# STM32L4S9xx register map
File version: 1.0
Registers are 32-bit, access not given, reset 0x0 unless marked. A register's access mark holds for its fields unless they carry their own. Offsets are from the block's base; [hi:lo] are bit positions; {n}, {i} and the like mark numbered series.

## CRS
Base 0x40006000
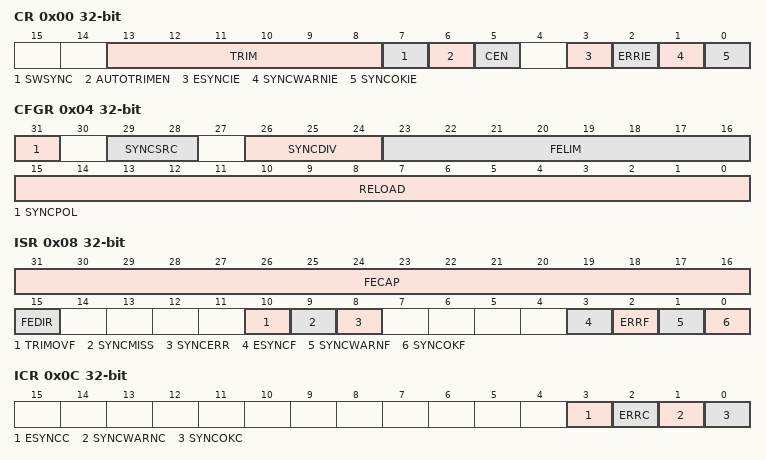
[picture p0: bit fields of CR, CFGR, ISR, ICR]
0x00 CR
  [13:8] TRIM, [7] SWSYNC, [6] AUTOTRIMEN, [5] CEN, [3] ESYNCIE, [2] ERRIE, [1] SYNCWARNIE, [0] SYNCOKIE
0x04 CFGR
  [31] SYNCPOL, [29:28] SYNCSRC, [26:24] SYNCDIV, [23:16] FELIM, [15:0] RELOAD
0x08 ISR
  [31:16] FECAP, [15] FEDIR, [10] TRIMOVF, [9] SYNCMISS, [8] SYNCERR, [3] ESYNCF, [2] ERRF, [1] SYNCWARNF, [0] SYNCOKF
0x0C ICR
  [3] ESYNCC, [2] ERRC, [1] SYNCWARNC, [0] SYNCOKC

## PWR
Base 0x40007000
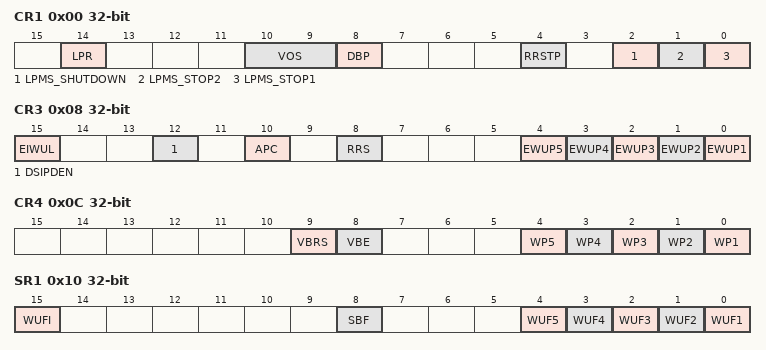
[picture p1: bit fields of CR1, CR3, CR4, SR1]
0x00 CR1
  [14] LPR, [10:9] VOS, [8] DBP, [4] RRSTP, [2] LPMS_SHUTDOWN, [1] LPMS_STOP2, [0] LPMS_STOP1
0x04 CR2
  [10] USV, [9] IOSV, [n+3] PVME{n} (n=1..4), [3] PLS_LEV4, [3:2] PLS_LEV6, [3:1] PLS_LEV7, [0] PVDE
0x08 CR3
  [15] EIWUL, [12] DSIPDEN, [10] APC, [8] RRS, [n-1] EWUP{n} (n=1..5)
0x0C CR4
  [9] VBRS, [8] VBE, [n-1] WP{n} (n=1..5)
0x10 SR1
  [15] WUFI, [8] SBF, [n-1] WUF{n} (n=1..5)
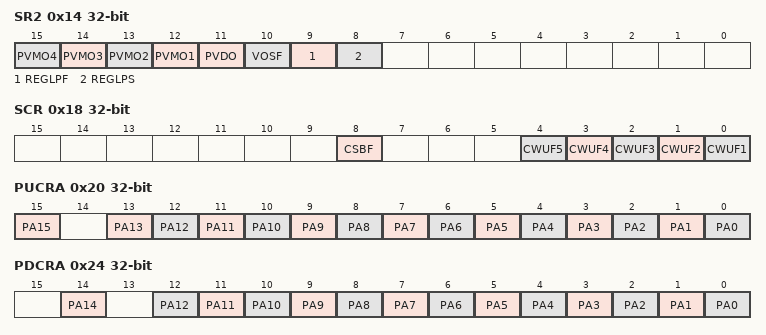
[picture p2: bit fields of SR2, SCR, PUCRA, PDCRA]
0x14 SR2
  [n+11] PVMO{n} (n=1..4), [11] PVDO, [10] VOSF, [9] REGLPF, [8] REGLPS
0x18 SCR
  [8] CSBF, [n-1] CWUF{n} (n=1..5)
0x20 PUCRA
  [15] PA15, [n] PA{n} (n=0..13)
0x24 PDCRA
  [14] PA14, [n] PA{n} (n=0..12)
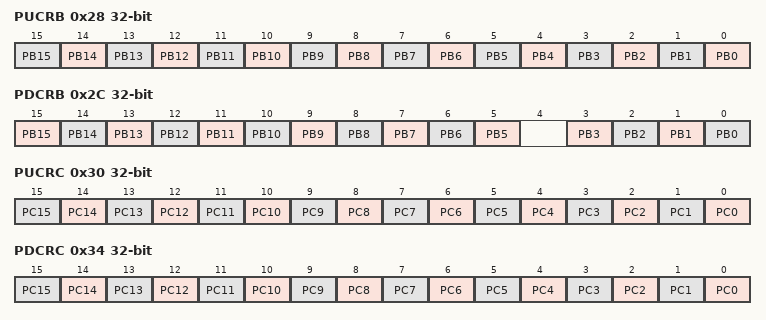
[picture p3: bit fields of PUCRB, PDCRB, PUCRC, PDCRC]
0x28 PUCRB
  [n] PB{n} (n=0..15)
0x2C PDCRB
  [n] PB{n} (n=5..15), [n] PB{n} (n=0..3)
0x30 PUCRC
  [n] PC{n} (n=0..15)
0x34 PDCRC
  [n] PC{n} (n=0..15)
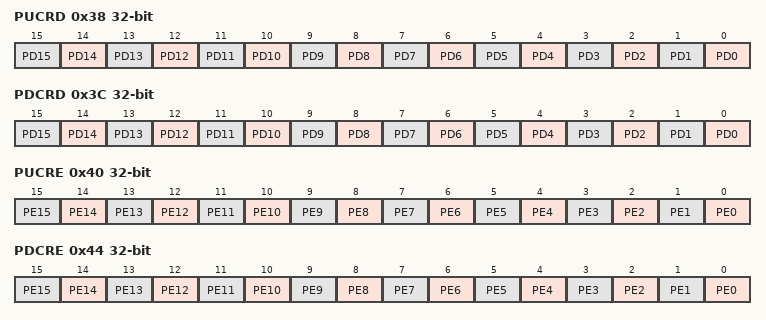
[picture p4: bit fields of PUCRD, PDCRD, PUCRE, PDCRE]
0x38 PUCRD
  [n] PD{n} (n=0..15)
0x3C PDCRD
  [n] PD{n} (n=0..15)
0x40 PUCRE
  [n] PE{n} (n=0..15)
0x44 PDCRE
  [n] PE{n} (n=0..15)
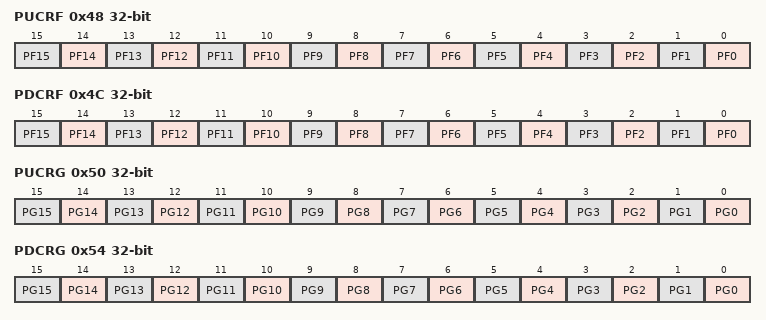
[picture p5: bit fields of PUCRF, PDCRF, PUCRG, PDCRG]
0x48 PUCRF
  [n] PF{n} (n=0..15)
0x4C PDCRF
  [n] PF{n} (n=0..15)
0x50 PUCRG
  [n] PG{n} (n=0..15)
0x54 PDCRG
  [n] PG{n} (n=0..15)
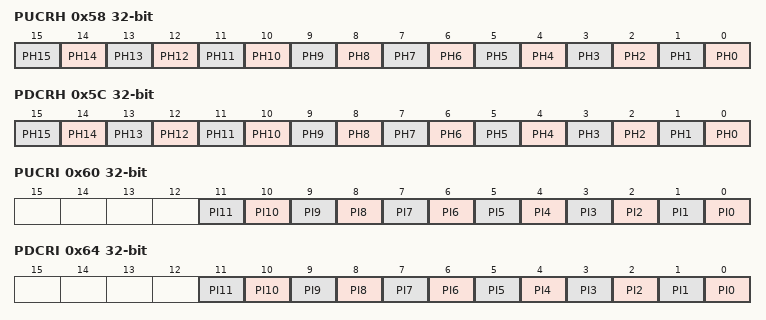
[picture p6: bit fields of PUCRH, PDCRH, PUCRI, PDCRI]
0x58 PUCRH
  [n] PH{n} (n=0..15)
0x5C PDCRH
  [n] PH{n} (n=0..15)
0x60 PUCRI
  [n] PI{n} (n=0..11)
0x64 PDCRI
  [n] PI{n} (n=0..11)
0x80 CR5
  [8] R1MODE

## DAC
Base 0x40007400
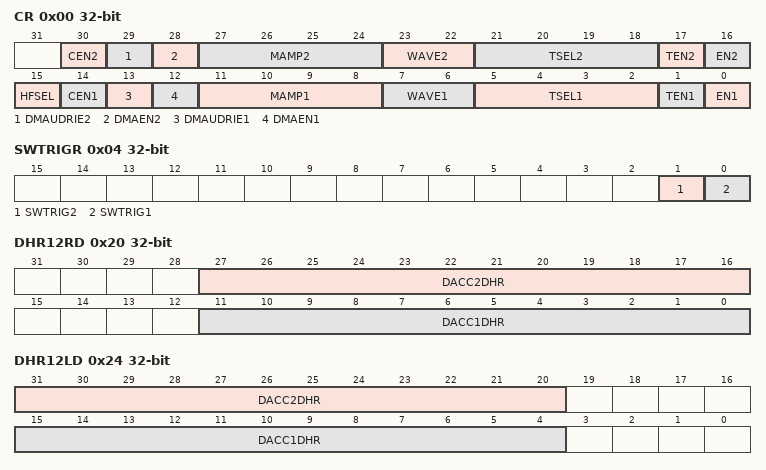
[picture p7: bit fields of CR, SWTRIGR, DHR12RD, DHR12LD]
0x00 CR
  [30] CEN2, [29] DMAUDRIE2, [28] DMAEN2, [27:24] MAMP2, [23:22] WAVE2, [21:18] TSEL2, [17] TEN2, [16] EN2, [15] HFSEL, [14] CEN1, [13] DMAUDRIE1, [12] DMAEN1, [11:8] MAMP1, [7:6] WAVE1, [5:2] TSEL1, [1] TEN1, [0] EN1
0x04 SWTRIGR
  [1] SWTRIG2, [0] SWTRIG1
0x08 DHR12R1
  [11:0] DACC1DHR
0x0C DHR12L1
  [15:4] DACC1DHR
0x10 DHR8R1
  [7:0] DACC1DHR
0x14 DHR12R2
  [11:0] DACC2DHR
0x18 DHR12L2
  [15:4] DACC2DHR
0x1C DHR8R2
  [7:0] DACC2DHR
0x20 DHR12RD
  [27:16] DACC2DHR, [11:0] DACC1DHR
0x24 DHR12LD
  [31:20] DACC2DHR, [15:4] DACC1DHR
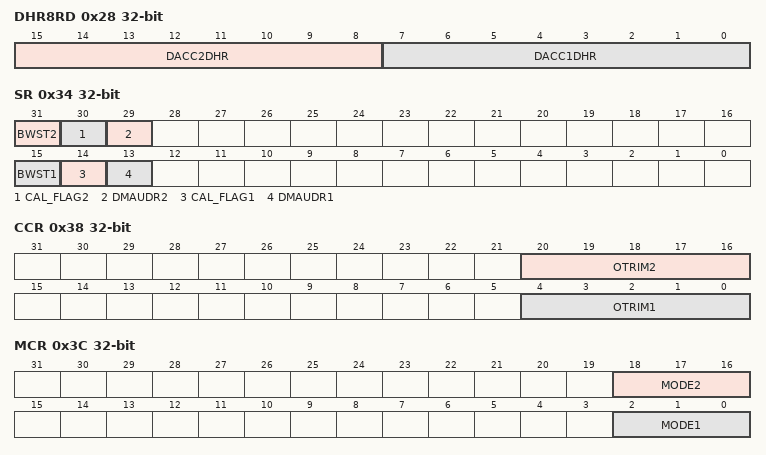
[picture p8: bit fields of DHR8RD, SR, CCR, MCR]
0x28 DHR8RD
  [15:8] DACC2DHR, [7:0] DACC1DHR
0x2C DOR1
  [11:0] DACC1DOR
0x30 DOR2
  [11:0] DACC2DOR
0x34 SR
  [31] BWST2, [30] CAL_FLAG2, [29] DMAUDR2, [15] BWST1, [14] CAL_FLAG1, [13] DMAUDR1
0x38 CCR
  [20:16] OTRIM2, [4:0] OTRIM1
0x3C MCR
  [18:16] MODE2, [2:0] MODE1
0x40 SHSR1
  [9:0] TSAMPLE1
0x44 SHSR2
  [9:0] TSAMPLE2
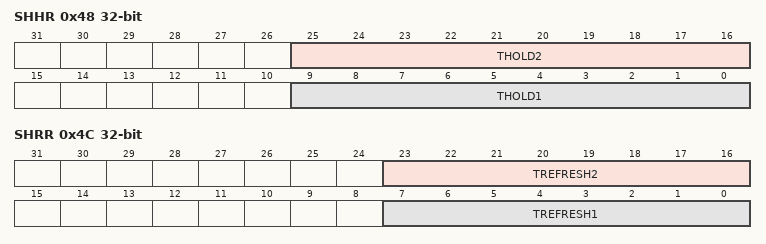
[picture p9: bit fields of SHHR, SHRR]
0x48 SHHR
  [25:16] THOLD2, [9:0] THOLD1
0x4C SHRR
  [23:16] TREFRESH2, [7:0] TREFRESH1

## DAC1
Base 0x40007400
Registers as DAC; these are added or differ:
0x08 DHR12R1
  [11:0] DACC1DHR
0x0C DHR12L1
  [15:4] DACC1DHR
0x10 DHR8R1
  [7:0] DACC1DHR
0x14 DHR12R2
  [11:0] DACC2DHR
0x18 DHR12L2
  [15:4] DACC2DHR
0x1C DHR8R2
  [7:0] DACC2DHR
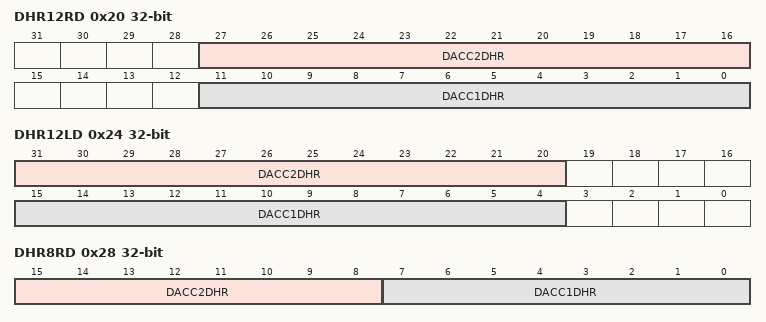
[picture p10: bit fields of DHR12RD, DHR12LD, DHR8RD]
0x20 DHR12RD
  [27:16] DACC2DHR, [11:0] DACC1DHR
0x24 DHR12LD
  [31:20] DACC2DHR, [15:4] DACC1DHR
0x28 DHR8RD
  [15:8] DACC2DHR, [7:0] DACC1DHR
0x2C DOR1
  [11:0] DACC1DOR
0x30 DOR2
  [11:0] DACC2DOR

## OPAMP1
Base 0x40007800
Same registers: OPAMP2 0x40007810
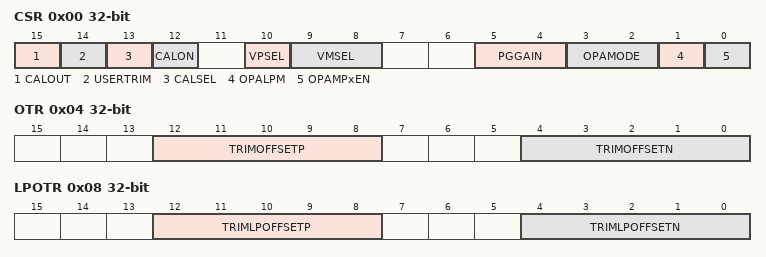
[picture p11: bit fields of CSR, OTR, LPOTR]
0x00 CSR
  [15] CALOUT, [14] USERTRIM, [13] CALSEL, [12] CALON, [10] VPSEL, [9:8] VMSEL, [5:4] PGGAIN, [3:2] OPAMODE, [1] OPALPM, [0] OPAMPxEN
0x04 OTR
  [12:8] TRIMOFFSETP, [4:0] TRIMOFFSETN
0x08 LPOTR
  [12:8] TRIMLPOFFSETP, [4:0] TRIMLPOFFSETN

## LPTIM1
Base 0x40007C00
Same registers: LPTIM2 0x40009400
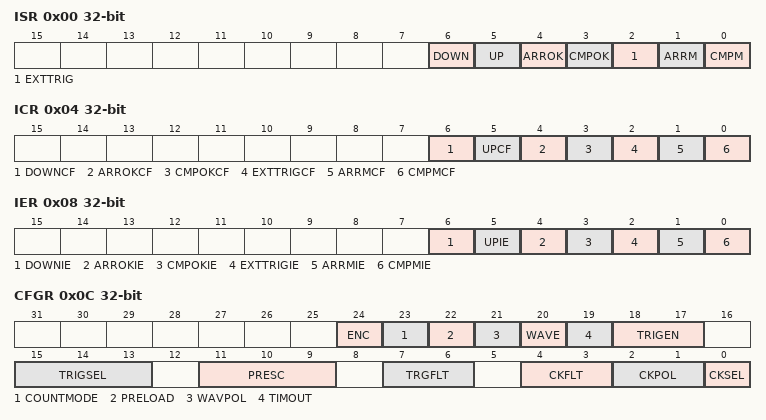
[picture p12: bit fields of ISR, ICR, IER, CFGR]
0x00 ISR
  [6] DOWN, [5] UP, [4] ARROK, [3] CMPOK, [2] EXTTRIG, [1] ARRM, [0] CMPM
0x04 ICR
  [6] DOWNCF, [5] UPCF, [4] ARROKCF, [3] CMPOKCF, [2] EXTTRIGCF, [1] ARRMCF, [0] CMPMCF
0x08 IER
  [6] DOWNIE, [5] UPIE, [4] ARROKIE, [3] CMPOKIE, [2] EXTTRIGIE, [1] ARRMIE, [0] CMPMIE
0x0C CFGR
  [24] ENC, [23] COUNTMODE, [22] PRELOAD, [21] WAVPOL, [20] WAVE, [19] TIMOUT, [18:17] TRIGEN, [15:13] TRIGSEL, [11:9] PRESC, [7:6] TRGFLT, [4:3] CKFLT, [2:1] CKPOL, [0] CKSEL
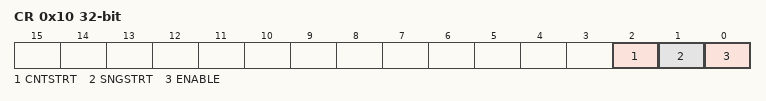
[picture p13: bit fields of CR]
0x10 CR
  [2] CNTSTRT, [1] SNGSTRT, [0] ENABLE
0x14 CMP
  [15:0] CMP
0x18 ARR
  [15:0] ARR
0x1C CNT
  [15:0] CNT
0x20 OR
  [1:0] OR
